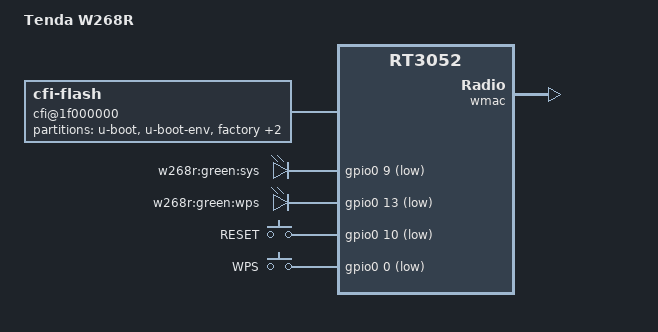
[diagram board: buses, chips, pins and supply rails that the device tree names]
/dts-v1/;

#include "rt3050.dtsi"

#include <dt-bindings/gpio/gpio.h>
#include <dt-bindings/input/input.h>

/ {
	compatible = "tenda,w268r", "ralink,rt3052-soc";
	model = "Tenda W268R";

	aliases {
		led-boot = &led_sys;
		led-failsafe = &led_sys;
		led-running = &led_sys;
		led-upgrade = &led_sys;
	};

	cfi@1f000000 {
		compatible = "cfi-flash";
		reg = <0x1f000000 0x800000>;
		bank-width = <2>;
		device-width = <2>;

		partitions {
			compatible = "fixed-partitions";
			#address-cells = <1>;
			#size-cells = <1>;

			partition@0 {
				label = "u-boot";
				reg = <0x0 0x30000>;
				read-only;
			};

			partition@30000 {
				label = "u-boot-env";
				reg = <0x30000 0x10000>;
				read-only;
			};

			factory: partition@40000 {
				label = "factory";
				reg = <0x40000 0x10000>;
				read-only;
			};

			partition@50000 {
				compatible = "denx,uimage";
				label = "firmware";
				reg = <0x50000 0x1a0000>;
			};

			partition@1f0000 {
				label = "owrt-config";
				reg = <0x1f0000 0x10000>;
			};
		};
	};

	leds {
		compatible = "gpio-leds";

		led_sys: sys {
			label = "w268r:green:sys";
			gpios = <&gpio0 9 GPIO_ACTIVE_LOW>;
		};

		wps {
			label = "w268r:green:wps";
			gpios = <&gpio0 13 GPIO_ACTIVE_LOW>;
		};
	};

	keys {
		compatible = "gpio-keys-polled";
		poll-interval = <20>;

		reset {
			label = "RESET";
			gpios = <&gpio0 10 GPIO_ACTIVE_LOW>;
			linux,code = <KEY_RESTART>;
		};

		wps {
			label = "WPS";
			gpios = <&gpio0 0 GPIO_ACTIVE_LOW>;
			linux,code = <KEY_WPS_BUTTON>;
		};
	};
};

&pinctrl {
	state_default: pinctrl0 {
		gpio {
			ralink,group = "spi", "i2c", "jtag", "rgmii", "mdio", "uartf";
			ralink,function = "gpio";
		};
	};
};

&ethernet {
	mtd-mac-address = <&factory 0x28>;
};

&esw {
	mediatek,portmap = <0x3e>;
};

&wmac {
	ralink,mtd-eeprom = <&factory 0>;
};
